# EFM32GG290F1024 register map
File version: 4.0.0
CPU: CM3 r2p1, little endian, MPU, no FPU, 3 interrupt priority bits
Registers are 32-bit, read-write, reset 0x0 unless marked. A register's access mark holds for its fields unless they carry their own. Offsets are from the block's base; [hi:lo] are bit positions; {n}, {i} and the like mark numbered series.

## DMA
Base 0x400C2000
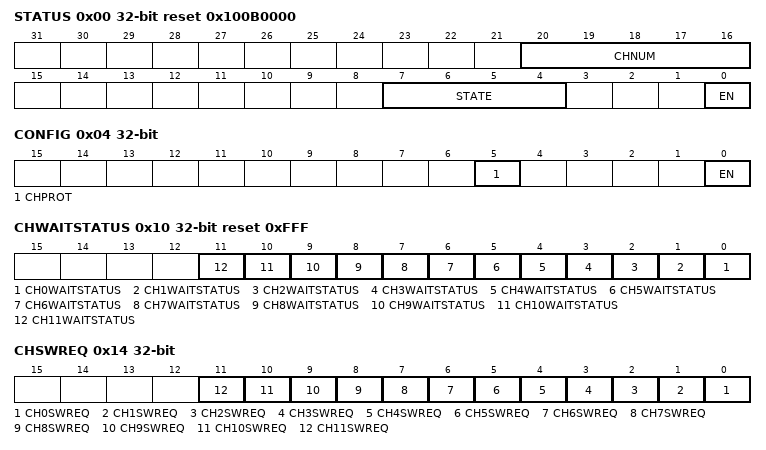
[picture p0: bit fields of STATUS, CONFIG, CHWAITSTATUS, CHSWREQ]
0x00 STATUS ro reset 0x100B0000 — DMA Status Registers
  [20:16] CHNUM — Channel Number
  [7:4] STATE — Control Current State
    0=IDLE; 1=RDCHCTRLDATA (Reading channel controller data); 2=RDSRCENDPTR (Reading source data end pointer); 3=RDDSTENDPTR (Reading destination data end pointer); 4=RDSRCDATA (Reading source data); 5=WRDSTDATA (Writing destination data); 6=WAITREQCLR (Waiting for DMA request to clear); 7=WRCHCTRLDATA (Writing channel controller data); 8=STALLED; 9=DONE; 10=PERSCATTRANS (Peripheral scatter-gather transition)
  [0] EN — DMA Enable Status
0x04 CONFIG wo — DMA Configuration Register
  [5] CHPROT — Channel Protection Control
  [0] EN — Enable DMA
0x08 CTRLBASE — Channel Control Data Base Pointer Register
  [31:0] CTRLBASE — Channel Control Data Base Pointer
0x0C ALTCTRLBASE ro reset 0x100 — Channel Alternate Control Data Base Pointer Register
  [31:0] ALTCTRLBASE — Channel Alternate Control Data Base Pointer
0x10 CHWAITSTATUS ro reset 0xFFF — Channel Wait on Request Status Register
  [n] CH{n}WAITSTATUS (n=0..11) — Channel {n} Wait on Request Status
0x14 CHSWREQ wo — Channel Software Request Register
  [n] CH{n}SWREQ (n=0..11) — Channel {n} Software Request
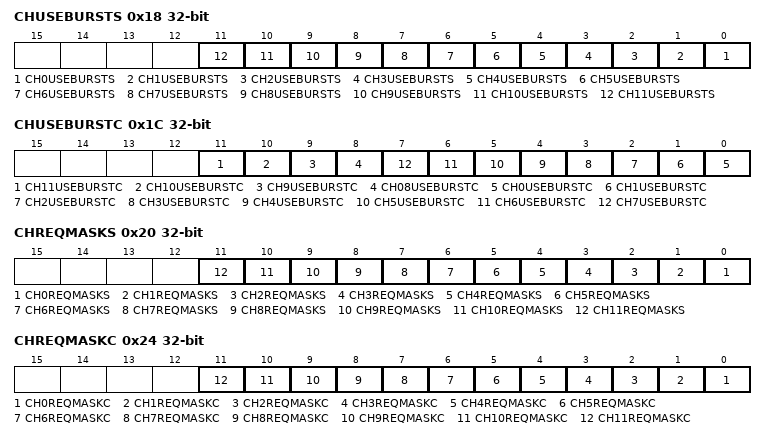
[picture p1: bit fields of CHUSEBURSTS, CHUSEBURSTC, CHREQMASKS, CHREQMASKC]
0x18 CHUSEBURSTS — Channel Useburst Set Register
  [n] CH{n}USEBURSTS (n=0..11) — Channel {n} Useburst Set
0x1C CHUSEBURSTC wo — Channel Useburst Clear Register
  [11] CH11USEBURSTC — Channel 11 Useburst Clear
  [10] CH10USEBURSTC — Channel 10 Useburst Clear
  [9] CH9USEBURSTC — Channel 9 Useburst Clear
  [8] CH08USEBURSTC — Channel 8 Useburst Clear
  [n] CH{n}USEBURSTC (n=0..7) — Channel {n} Useburst Clear
0x20 CHREQMASKS wo — Channel Request Mask Set Register
  [n] CH{n}REQMASKS (n=0..11) — Channel {n} Request Mask Set
0x24 CHREQMASKC wo — Channel Request Mask Clear Register
  [n] CH{n}REQMASKC (n=0..11) — Channel {n} Request Mask Clear
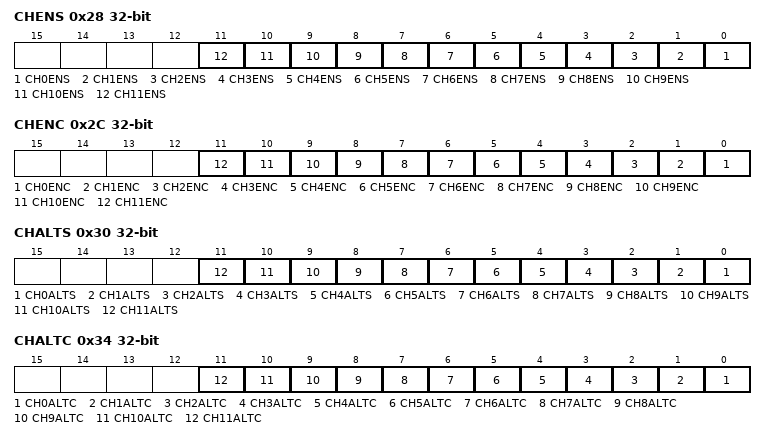
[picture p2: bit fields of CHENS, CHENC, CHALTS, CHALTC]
0x28 CHENS wo — Channel Enable Set Register
  [n] CH{n}ENS (n=0..11) — Channel {n} Enable Set
0x2C CHENC wo — Channel Enable Clear Register
  [n] CH{n}ENC (n=0..11) — Channel {n} Enable Clear
0x30 CHALTS wo — Channel Alternate Set Register
  [n] CH{n}ALTS (n=0..11) — Channel {n} Alternate Structure Set
0x34 CHALTC wo — Channel Alternate Clear Register
  [n] CH{n}ALTC (n=0..11) — Channel {n} Alternate Clear
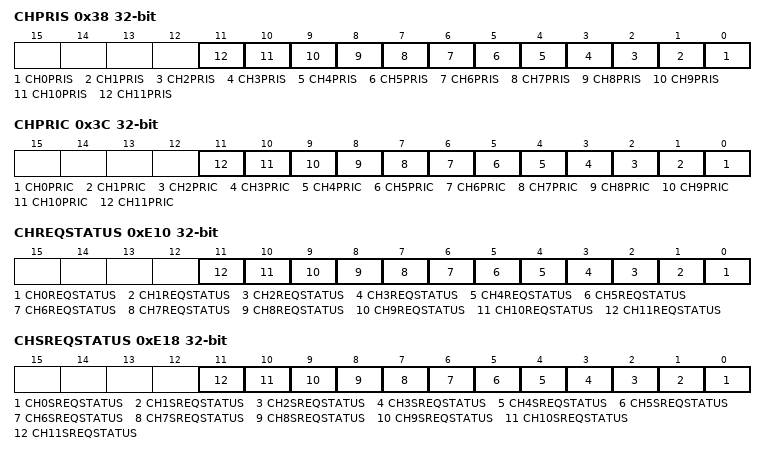
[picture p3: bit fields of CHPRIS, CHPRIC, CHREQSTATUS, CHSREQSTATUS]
0x38 CHPRIS wo — Channel Priority Set Register
  [n] CH{n}PRIS (n=0..11) — Channel {n} High Priority Set
0x3C CHPRIC wo — Channel Priority Clear Register
  [n] CH{n}PRIC (n=0..11) — Channel {n} High Priority Clear
0x4C ERRORC — Bus Error Clear Register
  [0] ERRORC — Bus Error Clear
0xE10 CHREQSTATUS ro — Channel Request Status
  [n] CH{n}REQSTATUS (n=0..11) — Channel {n} Request Status
0xE18 CHSREQSTATUS ro — Channel Single Request Status
  [n] CH{n}SREQSTATUS (n=0..11) — Channel {n} Single Request Status
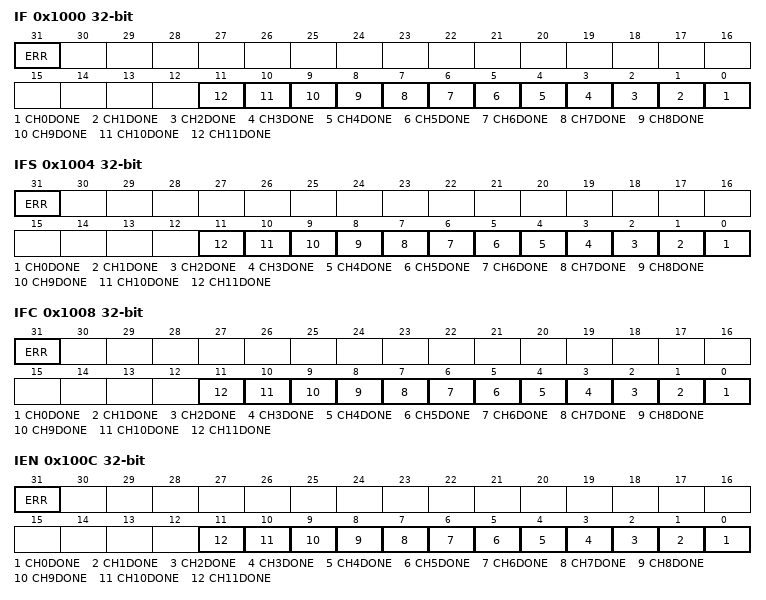
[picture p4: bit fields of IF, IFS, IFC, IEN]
0x1000 IF ro — Interrupt Flag Register
  [31] ERR — DMA Error Interrupt Flag
  [n] CH{n}DONE (n=0..11) — DMA Channel {n} Complete Interrupt Flag
0x1004 IFS wo — Interrupt Flag Set Register
  [31] ERR — DMA Error Interrupt Flag Set
  [n] CH{n}DONE (n=0..11) — DMA Channel {n} Complete Interrupt Flag Set
0x1008 IFC wo — Interrupt Flag Clear Register
  [31] ERR — DMA Error Interrupt Flag Clear
  [n] CH{n}DONE (n=0..11) — DMA Channel {n} Complete Interrupt Flag Clear
0x100C IEN — Interrupt Enable register
  [31] ERR — DMA Error Interrupt Flag Enable
  [n] CH{n}DONE (n=0..11) — DMA Channel {n} Complete Interrupt Enable
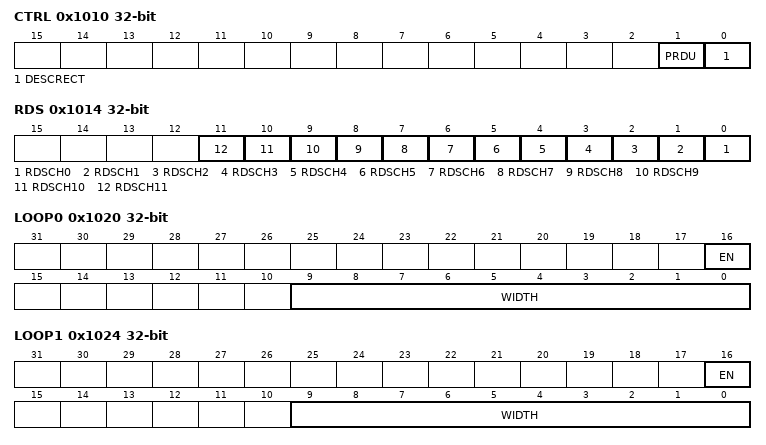
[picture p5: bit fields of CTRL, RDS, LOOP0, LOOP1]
0x1010 CTRL — DMA Control Register
  [1] PRDU — Prevent Rect Descriptor Update
  [0] DESCRECT — Descriptor Specifies Rectangle
0x1014 RDS — DMA Retain Descriptor State
  [n] RDSCH{n} (n=0..11) — Retain Descriptor State
0x1020 LOOP0 — Channel 0 Loop Register
  [16] EN — DMA Channel 0 Loop Enable
  [9:0] WIDTH — Loop Width
0x1024 LOOP1 — Channel 1 Loop Register
  [16] EN — DMA Channel 1 Loop Enable
  [9:0] WIDTH — DMA Channel 1 Loop Width
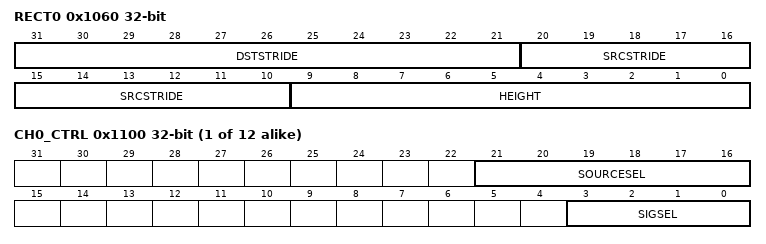
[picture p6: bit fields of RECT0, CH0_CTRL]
0x1060 RECT0 — Channel 0 Rectangle Register
  [31:21] DSTSTRIDE — DMA Channel 0 Destination Stride
  [20:10] SRCSTRIDE — DMA Channel 0 Source Stride
  [9:0] HEIGHT — DMA Channel 0 Rectangle Height
{0x1100+4i} CH{i}_CTRL (i=0..11) — Channel Control Register
  [21:16] SOURCESEL — Source Select
    0=NONE (No source selected); 8=ADC0 (Analog to Digital Converter 0); 10=DAC0 (Digital to Analog Converter 0); 12=USART0 (Universal Synchronous/Asynchronous Receiver/Transmitter 0); 13=USART1 (Universal Synchronous/Asynchronous Receiver/Transmitter 1); 14=USART2 (Universal Synchronous/Asynchronous Receiver/Transmitter 2); 16=LEUART0 (Low Energy UART 0); 17=LEUART1 (Low Energy UART 1); 20=I2C0; 21=I2C1; {v}=TIMER{v-24} (v=24..27); 44=UART0 (Universal Asynchronous Receiver/Transmitter 0); 45=UART1 (Universal Asynchronous Receiver/Transmitter 1); 48=MSC; 49=AES (Advanced Encryption Standard Accelerator); 50=LESENSE (Low Energy Sensor Interface); 51=EBI (External Bus Interface)
  [3:0] SIGSEL — Signal Select

## Notices in the file
# License
Copyright 2021 Silicon Laboratories Inc. www.silabs.com
SPDX-License-Identifier: Zlib
The licensor of this software is Silicon Laboratories Inc.
This software is provided 'as-is', without any express or implied
warranty. In no event will the authors be held liable for any damages
arising from the use of this software.
Permission is granted to anyone to use this software for any purpose,
including commercial applications, and to alter it and redistribute it
freely, subject to the following restrictions:
1. The origin of this software must not be misrepresented; you must not
claim that you wrote the original software. If you use this software
in a product, an acknowledgment in the product documentation would be
appreciated but is not required.
2. Altered source versions must be plainly marked as such, and must not be
misrepresented as being the original software.
3. This notice may not be removed or altered from any source distribution.
